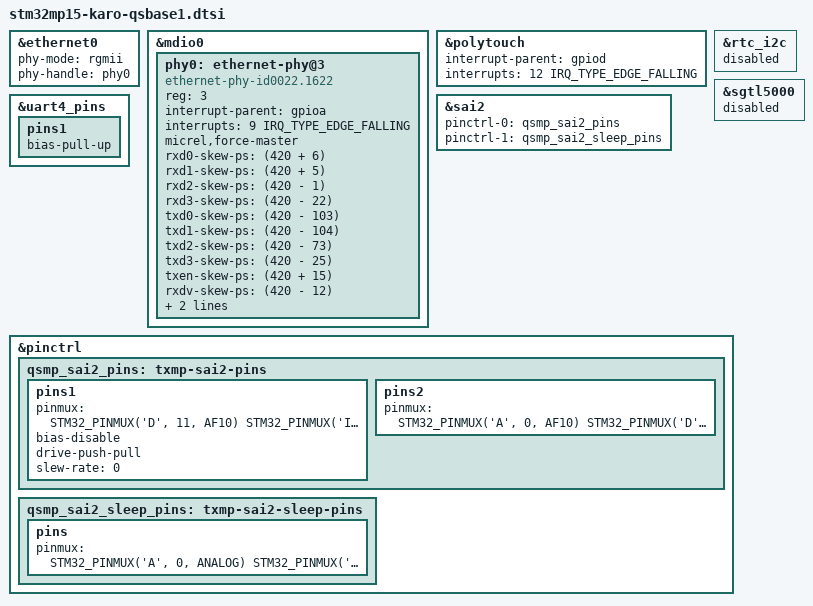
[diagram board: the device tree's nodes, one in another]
// SPDX-License-Identifier: (GPL-2.0 OR BSD-3-Clause)
/*
 * Copyright (C) 2020 Lothar Waßmann <LW@KARO-electronics.de>
 */

#include "stm32mp15-karo-mb7.dtsi"

/ {
	/delete-node/ sound;
};

&ethernet0 {
	phy-mode = "rgmii";
	phy-handle = <&phy0>;
	status = "okay";
};

&mdio0 {
	phy0: ethernet-phy@3 {
		compatible = "ethernet-phy-id0022.1622";
		reg = <3>;
		interrupt-parent = <&gpioa>;
		interrupts = <9 IRQ_TYPE_EDGE_FALLING>;
		micrel,force-master;
		rxd0-skew-ps = <(420 + 6)>;
		rxd1-skew-ps = <(420 + 5)>;
		rxd2-skew-ps = <(420 - 1)>;
		rxd3-skew-ps = <(420 - 22)>;
		txd0-skew-ps = <(420 - 103)>;
		txd1-skew-ps = <(420 - 104)>;
		txd2-skew-ps = <(420 - 73)>;
		txd3-skew-ps = <(420 - 25)>;
		txen-skew-ps = <(420 + 15)>;
		rxdv-skew-ps = <(420 - 12)>;
		rxc-skew-ps = <(900 + 0)>;
		txc-skew-ps = <(900 + 1000)>;
	};
};

&polytouch {
	interrupt-parent = <&gpiod>;
	interrupts = <12 IRQ_TYPE_EDGE_FALLING>;
	/delete-property/ reset-gpios;
	/delete-property/ wake-gpios;
};

&rtc_i2c {
	status = "disabled";
};

&sgtl5000 {
	status = "disabled";
};

&uart4_pins {
	pins1 {
		/delete-property/ bias-disable;
		bias-pull-up;
	};
};

&sai2 {
	pinctrl-0 = <&qsmp_sai2_pins>;
	pinctrl-1 = <&qsmp_sai2_sleep_pins>;
};

&pinctrl {
	qsmp_sai2_pins: txmp-sai2-pins {
		pins1 {
			pinmux = <
				STM32_PINMUX('D', 11, AF10)	/* TXD */
				STM32_PINMUX('I', 7, AF10)	/* FS */
			>;
			bias-disable;
			drive-push-pull;
			slew-rate = <0>;
		};

		pins2 {
			pinmux = <
				STM32_PINMUX('A', 0, AF10)	/* RXD */
				STM32_PINMUX('D', 13, AF10)	/* SCK */
			>;
		};
	};

	qsmp_sai2_sleep_pins: txmp-sai2-sleep-pins {
		pins {
			pinmux = <
				STM32_PINMUX('A', 0, ANALOG)	/* RXD */
				STM32_PINMUX('D', 11, ANALOG)	/* TXD */
				STM32_PINMUX('D', 13, ANALOG)	/* SCK */
				STM32_PINMUX('I', 7, ANALOG)	/* FS */
			>;
		};
	};
};
